# tac_data register map
Vendor: Texas Instruments
Peripheral module from a debugger description file (folder Keystone2).
Registers are 32-bit, access not given, no defined reset value unless marked. A register's access mark holds for its fields unless they carry their own. Offsets are as the file gives them; lines under a group give offsets from that group; [hi:lo] are bit positions; {n}, {i} and the like mark numbered series; 'fields as' and 'values as' point back to an identical list; <NAME> marks a mode.

## TAC_DATA
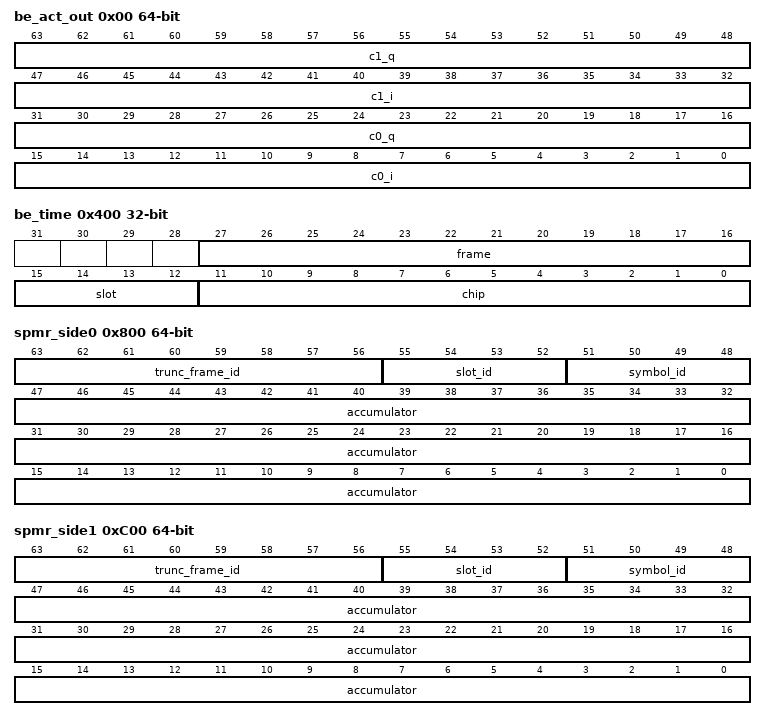
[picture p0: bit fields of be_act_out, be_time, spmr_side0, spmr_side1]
0x00 be_act_out 64-bit rw — (1 of 128, stride 8)
  [63:48] c1_q, [47:32] c1_i, [31:16] c0_q, [15:0] c0_i
0x400 be_time rw
  [27:16] frame, [15:12] slot, [11:0] chip
0x800 spmr_side0 64-bit rw — (1 of 128, stride 8)
  [63:56] trunc_frame_id, [55:52] slot_id, [51:48] symbol_id, [47:0] accumulator
0xC00 spmr_side1 64-bit rw — (1 of 128, stride 8)
  fields as spmr_side0
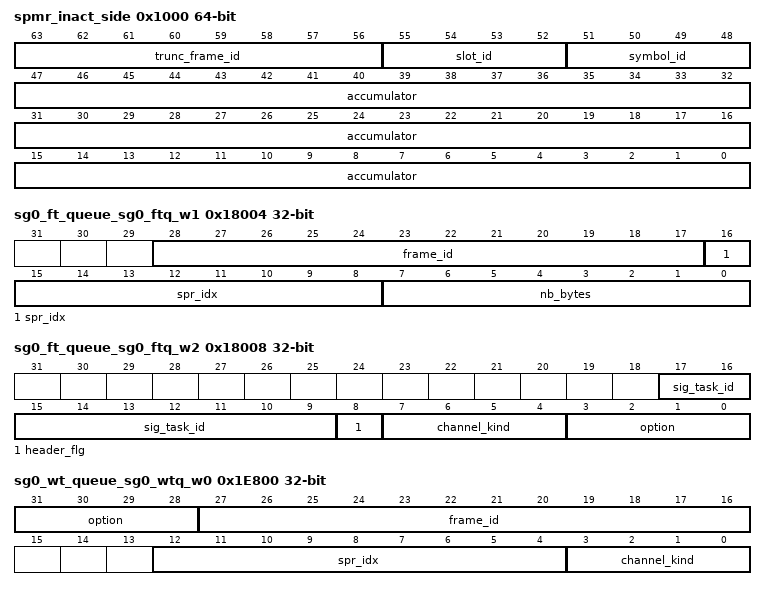
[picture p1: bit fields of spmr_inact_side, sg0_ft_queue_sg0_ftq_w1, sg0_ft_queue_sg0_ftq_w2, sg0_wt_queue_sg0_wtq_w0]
0x1000 spmr_inact_side 64-bit rw — (1 of 128, stride 8)
  fields as spmr_side0
0x4000 eab_wr rw — (1 of 1536, stride 4)
  [31:0] word
0x5800 eab_rd rw — (1 of 768, stride 4)
  [31:0] word
0x10000 sg0_sig_gain_sg0_sig_gain_w0 rw — (1 of 384, stride 64)
  [9:0] init_gain_sig4kplus0
0x10004 sg0_sig_gain_sg0_sig_gain_w1 rw — (1 of 384, stride 64)
  [7:0] delta_gain1_sig4kplus0
0x10008 sg0_sig_gain_sg0_sig_gain_w2 rw — (1 of 384, stride 64)
  [7:0] delta_gain2_sig4kplus0
0x10010 sg0_sig_gain_sg0_sig_gain_w4 rw — (1 of 384, stride 64)
  [9:0] init_gain_sig4kplus1
0x10014 sg0_sig_gain_sg0_sig_gain_w5 rw — (1 of 384, stride 64)
  [7:0] delta_gain1_sig4kplus1
0x10018 sg0_sig_gain_sg0_sig_gain_w6 rw — (1 of 384, stride 64)
  [7:0] delta_gain2_sig4kplus1
0x10020 sg0_sig_gain_sg0_sig_gain_w8 rw — (1 of 384, stride 64)
  [9:0] init_gain_sig4kplus2
0x10024 sg0_sig_gain_sg0_sig_gain_w9 rw — (1 of 384, stride 64)
  [7:0] delta_gain1_sig4kplus2
0x10028 sg0_sig_gain_sg0_sig_gain_w10 rw — (1 of 384, stride 64)
  [7:0] delta_gain2_sig4kplus2
0x10030 sg0_sig_gain_sg0_sig_gain_w12 rw — (1 of 384, stride 64)
  [9:0] init_gain_sig4kplus3
0x10034 sg0_sig_gain_sg0_sig_gain_w13 rw — (1 of 384, stride 64)
  [7:0] delta_gain1_sig4kplus3
0x10038 sg0_sig_gain_sg0_sig_gain_w14 rw — (1 of 384, stride 64)
  [7:0] delta_gain2_sig4kplus3
0x16000 sg0_sig_out rw — (1 of 2048, stride 4)
  [31:0] word
0x18000 sg0_ft_queue_sg0_ftq_w0 rw — (1 of 512, stride 16)
  [31:0] start_addr
0x18004 sg0_ft_queue_sg0_ftq_w1 rw — (1 of 512, stride 16)
  [28:17] frame_id, [16:8] spr_idx, [7:0] nb_bytes
0x18008 sg0_ft_queue_sg0_ftq_w2 rw — (1 of 512, stride 16)
  [17:9] sig_task_id, [8] header_flg, [7:4] channel_kind, [3:0] option
0x1A000 sg0_ib rw — (1 of 2048, stride 4)
  [31:0] word
0x1C000 sg0_ob0 rw — (1 of 1024, stride 4)
  [31:0] word
0x1D000 sg0_ob1 rw — (1 of 1024, stride 4)
  [31:0] word
0x1E800 sg0_wt_queue_sg0_wtq_w0 rw — (1 of 128, stride 8)
  [31:28] option, [27:16] frame_id, [12:4] spr_idx, [3:0] channel_kind
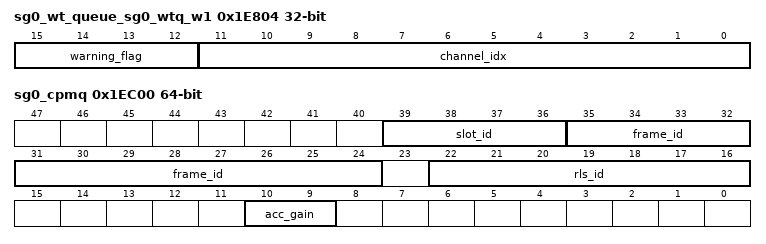
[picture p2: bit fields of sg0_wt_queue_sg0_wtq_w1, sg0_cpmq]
0x1E804 sg0_wt_queue_sg0_wtq_w1 rw — (1 of 128, stride 8)
  [15:12] warning_flag, [11:0] channel_idx
0x1EC00 sg0_cpmq 64-bit rw — (1 of 128, stride 8)
  [39:36] slot_id, [35:24] frame_id, [22:16] rls_id, [10:9] acc_gain
0x1F000 sg0_sig_input rw — (1 of 768, stride 4)
  [19:0] sig_data
{0x20000+4i} sg1_sig_gain_sg1_sig_gain_w{i} (i=0..2) — (1 of 384, stride 64)
{0x20000+4i} sg1_sig_gain_sg1_sig_gain_w{i} (i=4..6) — (1 of 384, stride 64)
0x20020 sg1_sig_gain_sg1_sig_gain_w7 — (1 of 384, stride 64)
0x20024 sg1_sig_gain_sg1_sig_gain_w8 — (1 of 384, stride 64)
0x20028 sg1_sig_gain_sg1_sig_gain_w10 — (1 of 384, stride 64)
{0x20000+4i} sg1_sig_gain_sg1_sig_gain_w{i} (i=12..14) — (1 of 384, stride 64)
{0x16000+0x10000*i} sg{i}_sig_out (i=1..3) — (1 of 2048, stride 4)
{0x28000+4i} sg1_ft_queue_sg1_ftq_w{i} (i=0..2) — (1 of 512, stride 16)
{0x1A000+0x10000*i} sg{i}_ib (i=1..3) — (1 of 2048, stride 4)
{0x1C000+0x10000*i} sg{i}_ob0 (i=1..3) — (1 of 1024, stride 4)
{0x1D000+0x10000*i} sg{i}_ob1 (i=1..3) — (1 of 1024, stride 4)
0x2E800 sg1_wt_queue_sg1_wtq_w0 — (1 of 128, stride 8)
0x2E804 sg1_wt_queue_sg1_wtq_w1 — (1 of 128, stride 8)
{0x1EC00+0x10000*i} sg{i}_cpmq 64-bit (i=1..3) — (1 of 128, stride 8)
{0x1F000+0x10000*i} sg{i}_sig_input (i=1..3) — (1 of 768, stride 4)
{0x30000+4i} sg2_sig_gain_sg2_sig_gain_w{i} (i=0..2) — (1 of 384, stride 64)
{0x30000+4i} sg2_sig_gain_sg2_sig_gain_w{i} (i=4..6) — (1 of 384, stride 64)
{0x30000+4i} sg2_sig_gain_sg2_sig_gain_w{i} (i=8..10) — (1 of 384, stride 64)
{0x30000+4i} sg2_sig_gain_sg2_sig_gain_w{i} (i=12..14) — (1 of 384, stride 64)
{0x38000+4i} sg2_ft_queue_sg2_ftq_w{i} (i=0..2) — (1 of 512, stride 16)
0x3E800 sg2_wt_queue_sg2_wtq_w0 — (1 of 128, stride 8)
0x3E804 sg2_wt_queue_sg2_wtq_w1 — (1 of 128, stride 8)
{0x40000+4i} sg3_sig_gain_sg3_sig_gain_w{i} (i=0..2) — (1 of 384, stride 64)
{0x40000+4i} sg3_sig_gain_sg3_sig_gain_w{i} (i=4..6) — (1 of 384, stride 64)
{0x40000+4i} sg3_sig_gain_sg3_sig_gain_w{i} (i=8..10) — (1 of 384, stride 64)
{0x40000+4i} sg3_sig_gain_sg3_sig_gain_w{i} (i=12..14) — (1 of 384, stride 64)
{0x48000+4i} sg3_ft_queue_sg3_ftq_w{i} (i=0..2) — (1 of 512, stride 16)
0x4E800 sg3_wt_queue_sg3_wtq_w0 — (1 of 128, stride 8)
0x4E804 sg3_wt_queue_sg3_wtq_w1 — (1 of 128, stride 8)
